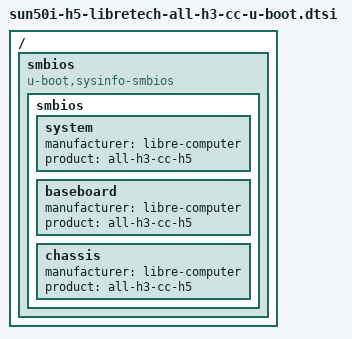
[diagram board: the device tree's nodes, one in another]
#include "sunxi-u-boot.dtsi"

/ {
	smbios {
		compatible = "u-boot,sysinfo-smbios";

		smbios {
			system {
				manufacturer = "libre-computer";
				product = "all-h3-cc-h5";
			};

			baseboard {
				manufacturer = "libre-computer";
				product = "all-h3-cc-h5";
			};

			chassis {
				manufacturer = "libre-computer";
				product = "all-h3-cc-h5";
			};
		};
	};
};
